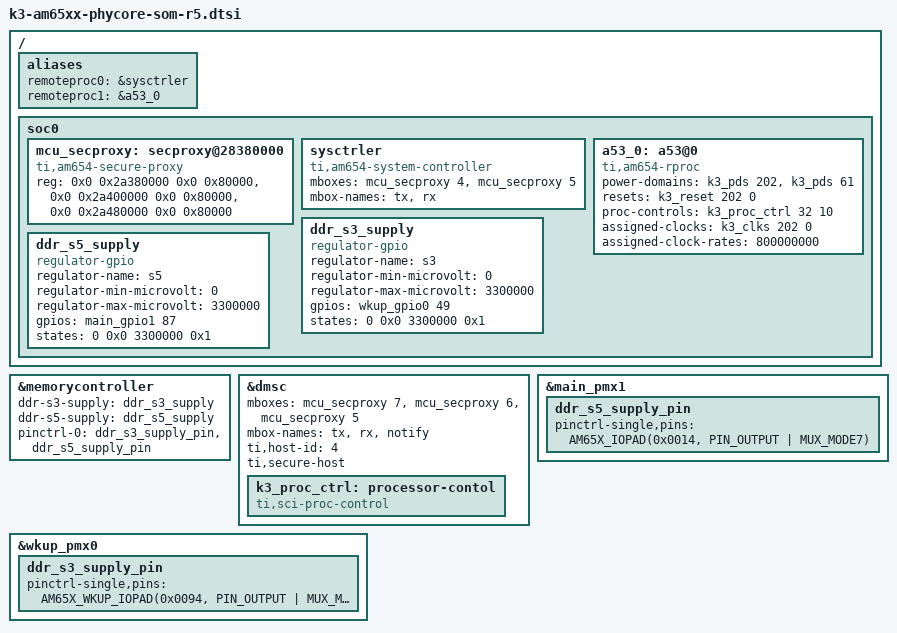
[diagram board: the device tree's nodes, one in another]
// SPDX-License-Identifier: GPL-2.0
/*
 * Copyright (C) 2018 PHYTEC America, LLC - https://www.phytec.com
 */

#include "k3-am6.dtsi"
#include "k3-am65xx-phycore-som-ddr4-512M16_x2.dtsi"
#include "k3-am654-ddr.dtsi"

/ {
	aliases {
		remoteproc0 = &sysctrler;
		remoteproc1 = &a53_0;
	};

	soc0 {
		mcu_secproxy: secproxy@28380000 {
			compatible = "ti,am654-secure-proxy";
			reg = <0x0 0x2a380000 0x0 0x80000>,
			      <0x0 0x2a400000 0x0 0x80000>,
			      <0x0 0x2a480000 0x0 0x80000>;
			reg-names = "rt", "scfg", "target_data";
			#mbox-cells = <1>;
			u-boot,dm-spl;
		};

		sysctrler: sysctrler {
			compatible = "ti,am654-system-controller";
			mboxes= <&mcu_secproxy 4>, <&mcu_secproxy 5>;
			mbox-names = "tx", "rx";
			u-boot,dm-spl;
		};

		a53_0: a53@0 {
			compatible = "ti,am654-rproc";
			power-domains = <&k3_pds 202>,
					<&k3_pds 61>;
			resets = <&k3_reset 202 0>;
			proc-controls = <&k3_proc_ctrl 32 10>;
			assigned-clocks = <&k3_clks 202 0>;
			assigned-clock-rates = <800000000>;
			u-boot,dm-spl;
		};

		ddr_s3_supply: ddr_s3_supply {
			compatible = "regulator-gpio";
			regulator-name = "s3";
			regulator-min-microvolt = <0>;
			regulator-max-microvolt = <3300000>;
			gpios = <&wkup_gpio0 49 GPIO_ACTIVE_HIGH>;
			states = <0 0x0 3300000 0x1>;
			u-boot,dm-spl;
		};

		ddr_s5_supply: ddr_s5_supply {
			compatible = "regulator-gpio";
			regulator-name = "s5";
			regulator-min-microvolt = <0>;
			regulator-max-microvolt = <3300000>;
			gpios = <&main_gpio1 87 GPIO_ACTIVE_HIGH>;
			states = <0 0x0 3300000 0x1>;
			u-boot,dm-spl;
		};
	};
};

&memorycontroller {
	ddr-s3-supply = <&ddr_s3_supply>;
	ddr-s5-supply = <&ddr_s5_supply>;
	pinctrl-names = "default";
	pinctrl-0 = <&ddr_s3_supply_pin &ddr_s5_supply_pin>;
};

&dmsc {
	mboxes= <&mcu_secproxy 7>, <&mcu_secproxy 6>, <&mcu_secproxy 5>;
	mbox-names = "tx", "rx", "notify";
	ti,host-id = <4>;
	ti,secure-host;

	k3_proc_ctrl: processor-contol {
		compatible = "ti,sci-proc-control";
		#proc-cells = <2>;
		u-boot,dm-spl;
	};
};

&main_pmx1 {
	ddr_s5_supply_pin: ddr_s5_supply_pin {
		pinctrl-single,pins = <
			AM65X_IOPAD(0x0014, PIN_OUTPUT | MUX_MODE7)	/* (A22) EXT_REFCLK1.GPIO1_87 */
		>;
		u-boot,dm-spl;
	};
};

&wkup_pmx0 {
	ddr_s3_supply_pin: ddr_s3_supply_pin {
		pinctrl-single,pins = <
			AM65X_WKUP_IOPAD(0x0094, PIN_OUTPUT | MUX_MODE7)	/* (Y3) MCU_SPI0_D0.WKUP_GPIO0_49 */
		>;
		u-boot,dm-spl;
	};
};
